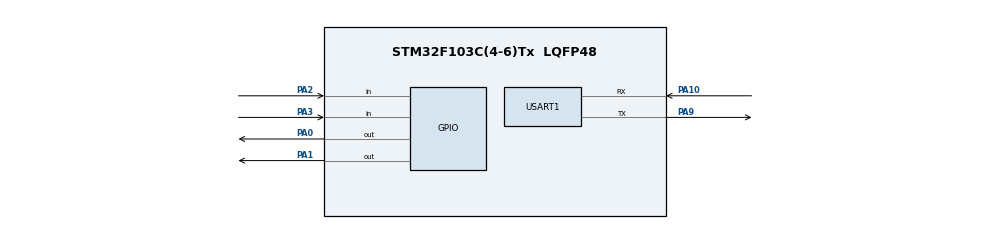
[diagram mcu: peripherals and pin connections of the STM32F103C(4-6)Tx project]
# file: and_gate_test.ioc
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Mcu.Family=STM32F1
Mcu.Name=STM32F103C(4-6)Tx
Mcu.Package=LQFP48
NVIC.PriorityGroup=NVIC_PRIORITYGROUP_4
PA0-WKUP.Signal=GPIO_Output
PA1.Signal=GPIO_Output
PA10.Mode=Asynchronous
PA10.Signal=USART1_RX
PA2.Signal=GPIO_Input
PA3.Signal=GPIO_Input
PA9.Mode=Asynchronous
PA9.Signal=USART1_TX
ProjectManager.HeapSize=0x200
ProjectManager.StackSize=0x400
ProjectManager.TargetToolchain=STM32CubeIDE
RCC.APB1Freq_Value=8000000
RCC.APB2Freq_Value=8000000
USART1.VirtualMode=VM_ASYNC
VP_SYS_VS_ND.Mode=No_Debug
board=custom

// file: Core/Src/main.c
/* USER CODE BEGIN Header */
/**
  ******************************************************************************
  * @file           : main.c
  * @brief          : Main program body
  ******************************************************************************
  * @attention
  *
  * <h2><center>&copy; Copyright (c) 2020 STMicroelectronics.
  * All rights reserved.</center></h2>
  *
  * This software component is licensed by ST under BSD 3-Clause license,
  * the "License"; You may not use this file except in compliance with the
  * License. You may obtain a copy of the License at:
  *                        opensource.org/licenses/BSD-3-Clause
  *
  ******************************************************************************
  */
/* USER CODE END Header */
#include "main.h"

UART_HandleTypeDef huart1;

void SystemClock_Config(void);
static void MX_GPIO_Init(void);
static void MX_USART1_UART_Init(void);

/* USER CODE BEGIN 0 */

int truthTable[][3] = {
		{GPIO_PIN_RESET,GPIO_PIN_RESET,GPIO_PIN_RESET},
		{GPIO_PIN_RESET,GPIO_PIN_SET,GPIO_PIN_RESET},
		{GPIO_PIN_RESET,GPIO_PIN_RESET,GPIO_PIN_RESET},
		{GPIO_PIN_SET,GPIO_PIN_SET,GPIO_PIN_SET}
};

/* USER CODE END 0 */

int main(void)
{

  /* MCU Configuration--------------------------------------------------------*/

  /* Reset of all peripherals, Initializes the Flash interface and the Systick. */
  HAL_Init();

  /* Configure the system clock */
  SystemClock_Config();

  /* Initialize all configured peripherals */
  MX_GPIO_Init();
  MX_USART1_UART_Init();

  /* Infinite loop */
  while (1)
  {
	if(HAL_GPIO_ReadPin(GPIOA, GPIO_PIN_3) == GPIO_PIN_SET)
	{
		printf("testing started \n\r");
		int flag = 1;
		for(int i = 0 ; i < 4 ; i++)
		{
			printf("testing... \n\r");
			HAL_GPIO_WritePin(GPIOA, GPIO_PIN_0, truthTable[i][0]);
			HAL_GPIO_WritePin(GPIOA, GPIO_PIN_1, truthTable[i][1]);

			if(HAL_GPIO_ReadPin(GPIOA, GPIO_PIN_2) != truthTable[i][2])
			{
				flag = 0;
				break;
			}
			HAL_Delay(1000);
		}
		if(flag == 1)
			printf("\n\r ic working - 74 08 \n\r");
		else
			printf("\n\r ic not working - 74 08 \n\r");
	}
  }
}

void SystemClock_Config(void)
{
  RCC_OscInitTypeDef RCC_OscInitStruct = {0};
  RCC_ClkInitTypeDef RCC_ClkInitStruct = {0};

  /** Initializes the RCC Oscillators according to the specified parameters
  * in the RCC_OscInitTypeDef structure.
  */
  RCC_OscInitStruct.OscillatorType = RCC_OSCILLATORTYPE_HSI;
  RCC_OscInitStruct.HSIState = RCC_HSI_ON;
  RCC_OscInitStruct.HSICalibrationValue = RCC_HSICALIBRATION_DEFAULT;
  RCC_OscInitStruct.PLL.PLLState = RCC_PLL_NONE;
  if (HAL_RCC_OscConfig(&RCC_OscInitStruct) != HAL_OK)
  {
    Error_Handler();
  }
  /** Initializes the CPU, AHB and APB buses clocks
  */
  RCC_ClkInitStruct.ClockType = RCC_CLOCKTYPE_HCLK|RCC_CLOCKTYPE_SYSCLK
                              |RCC_CLOCKTYPE_PCLK1|RCC_CLOCKTYPE_PCLK2;
  RCC_ClkInitStruct.SYSCLKSource = RCC_SYSCLKSOURCE_HSI;
  RCC_ClkInitStruct.AHBCLKDivider = RCC_SYSCLK_DIV1;
  RCC_ClkInitStruct.APB1CLKDivider = RCC_HCLK_DIV1;
  RCC_ClkInitStruct.APB2CLKDivider = RCC_HCLK_DIV1;

  if (HAL_RCC_ClockConfig(&RCC_ClkInitStruct, FLASH_LATENCY_0) != HAL_OK)
  {
    Error_Handler();
  }
}

static void MX_USART1_UART_Init(void)
{

  huart1.Instance = USART1;
  huart1.Init.BaudRate = 115200;
  huart1.Init.WordLength = UART_WORDLENGTH_8B;
  huart1.Init.StopBits = UART_STOPBITS_1;
  huart1.Init.Parity = UART_PARITY_NONE;
  huart1.Init.Mode = UART_MODE_TX_RX;
  huart1.Init.HwFlowCtl = UART_HWCONTROL_NONE;
  huart1.Init.OverSampling = UART_OVERSAMPLING_16;
  if (HAL_UART_Init(&huart1) != HAL_OK)
  {
    Error_Handler();
  }
  /* USER CODE BEGIN USART1_Init 2 */
  printf("tester initialized! \n\r");
  /* USER CODE END USART1_Init 2 */

}

static void MX_GPIO_Init(void)
{
  GPIO_InitTypeDef GPIO_InitStruct = {0};

  /* GPIO Ports Clock Enable */
  __HAL_RCC_GPIOA_CLK_ENABLE();

  /*Configure GPIO pin Output Level */
  HAL_GPIO_WritePin(GPIOA, GPIO_PIN_0|GPIO_PIN_1, GPIO_PIN_RESET);

  /*Configure GPIO pins : PA0 PA1 */
  GPIO_InitStruct.Pin = GPIO_PIN_0|GPIO_PIN_1;
  GPIO_InitStruct.Mode = GPIO_MODE_OUTPUT_PP;
  GPIO_InitStruct.Pull = GPIO_NOPULL;
  GPIO_InitStruct.Speed = GPIO_SPEED_FREQ_LOW;
  HAL_GPIO_Init(GPIOA, &GPIO_InitStruct);

  /*Configure GPIO pins : PA2 PA3 */
  GPIO_InitStruct.Pin = GPIO_PIN_2|GPIO_PIN_3;
  GPIO_InitStruct.Mode = GPIO_MODE_INPUT;
  GPIO_InitStruct.Pull = GPIO_NOPULL;
  HAL_GPIO_Init(GPIOA, &GPIO_InitStruct);

}

void Error_Handler(void)
{
  __disable_irq();
  while (1)
  {
  }
}

#ifdef __GNUC__
  /* With GCC/RAISONANCE, small printf (option LD Linker->Libraries->Small printf
     set to 'Yes') calls __io_putchar() */
  #define PUTCHAR_PROTOTYPE int __io_putchar(int ch)
#else
  #define PUTCHAR_PROTOTYPE int fputc(int ch, FILE *f)
#endif /* __GNUC__ */
/**
  * @brief  Retargets the C library printf function to the USART.
  * @param  None
  * @retval None
  */
PUTCHAR_PROTOTYPE
{
  /* Place your implementation of fputc here */
  /* e.g. write a character to the EVAL_COM1 and Loop until the end of transmission */
  HAL_UART_Transmit(&huart1, (uint8_t *)&ch, 1, 0xFFFF);

  return ch;
}

/************************ (C) COPYRIGHT STMicroelectronics *****END OF FILE****/
